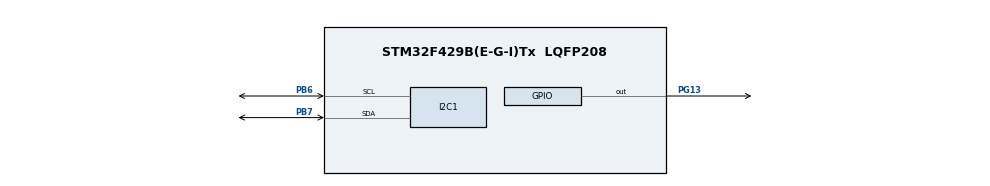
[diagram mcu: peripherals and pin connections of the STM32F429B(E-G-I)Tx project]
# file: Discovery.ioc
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FREERTOS.Tasks01=Led_on_task,2,128,Led_on_task_callback;Led_off_task,2,128,Led_off_task_callback;supervisor,0,128,supervisor_callback
FREERTOS.configTOTAL_HEAP_SIZE=10240
I2C1.OwnAddress=1
Mcu.Family=STM32F4
Mcu.Name=STM32F429B(E-G-I)Tx
Mcu.Package=LQFP208
NVIC.PriorityGroup=NVIC_PRIORITYGROUP_4
PB6.Mode=I2C
PB6.Signal=I2C1_SCL
PB7.Mode=I2C
PB7.Signal=I2C1_SDA
PG13.Signal=GPIO_Output
ProjectManager.TargetToolchain=EWARM
RCC.AHBFreq_Value=16000000
RCC.APB1Freq_Value=16000000
RCC.APB2Freq_Value=16000000
RCC.CortexFreq_Value=16000000
RCC.HSE_VALUE=25000000
RCC.HSI_VALUE=16000000
RCC.LSE_VALUE=32768
RCC.SYSCLKFreq_VALUE=16000000
RCC.VCOOutputFreq_Value=192000000
VP_FREERTOS_VS_ENABLE.Mode=Enabled
board=Discovery

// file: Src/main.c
/**
  ******************************************************************************
  * File Name          : main.c
  * Description        : Main program body
  ******************************************************************************
  *
  * COPYRIGHT(c) 2015 STMicroelectronics
  *
  * Redistribution and use in source and binary forms, with or without modification,
  * are permitted provided that the following conditions are met:
  *   1. Redistributions of source code must retain the above copyright notice,
  *      this list of conditions and the following disclaimer.
  *   2. Redistributions in binary form must reproduce the above copyright notice,
  *      this list of conditions and the following disclaimer in the documentation
  *      and/or other materials provided with the distribution.
  *   3. Neither the name of STMicroelectronics nor the names of its contributors
  *      may be used to endorse or promote products derived from this software
  *      without specific prior written permission.
  *
  * THIS SOFTWARE IS PROVIDED BY THE COPYRIGHT HOLDERS AND CONTRIBUTORS "AS IS"
  * AND ANY EXPRESS OR IMPLIED WARRANTIES, INCLUDING, BUT NOT LIMITED TO, THE
  * IMPLIED WARRANTIES OF MERCHANTABILITY AND FITNESS FOR A PARTICULAR PURPOSE ARE
  * DISCLAIMED. IN NO EVENT SHALL THE COPYRIGHT HOLDER OR CONTRIBUTORS BE LIABLE
  * FOR ANY DIRECT, INDIRECT, INCIDENTAL, SPECIAL, EXEMPLARY, OR CONSEQUENTIAL
  * DAMAGES (INCLUDING, BUT NOT LIMITED TO, PROCUREMENT OF SUBSTITUTE GOODS OR
  * SERVICES; LOSS OF USE, DATA, OR PROFITS; OR BUSINESS INTERRUPTION) HOWEVER
  * CAUSED AND ON ANY THEORY OF LIABILITY, WHETHER IN CONTRACT, STRICT LIABILITY,
  * OR TORT (INCLUDING NEGLIGENCE OR OTHERWISE) ARISING IN ANY WAY OUT OF THE USE
  * OF THIS SOFTWARE, EVEN IF ADVISED OF THE POSSIBILITY OF SUCH DAMAGE.
  *
  ******************************************************************************
  */
#include "stm32f4xx_hal.h"
#include "cmsis_os.h"

I2C_HandleTypeDef hi2c1;

osThreadId Led_on_taskHandle;
osThreadId Led_off_taskHandle;
osThreadId supervisorHandle;

/* USER CODE BEGIN PV */
/* Private variables ---------------------------------------------------------*/
uint8_t pData[1] = {0xF};
/* USER CODE END PV */

void SystemClock_Config(void);
static void MX_GPIO_Init(void);
static void MX_I2C1_Init(void);
void Led_on_task_callback(void const * argument);
void Led_off_task_callback(void const * argument);
void supervisor_callback(void const * argument);

/* USER CODE BEGIN PFP */
/* Private function prototypes -----------------------------------------------*/

/* USER CODE END PFP */

int main(void)
{

  /* MCU Configuration----------------------------------------------------------*/

  /* Reset of all peripherals, Initializes the Flash interface and the Systick. */
  HAL_Init();

  /* Configure the system clock */
  SystemClock_Config();

  /* Initialize all configured peripherals */
  MX_GPIO_Init();
  MX_I2C1_Init();

  /* Create the thread(s) */
  /* definition and creation of Led_on_task */
  osThreadDef(Led_on_task, Led_on_task_callback, osPriorityHigh, 0, 128);
  Led_on_taskHandle = osThreadCreate(osThread(Led_on_task), NULL);

  /* definition and creation of Led_off_task */
  osThreadDef(Led_off_task, Led_off_task_callback, osPriorityHigh, 0, 128);
  Led_off_taskHandle = osThreadCreate(osThread(Led_off_task), NULL);

  /* definition and creation of supervisor */
  osThreadDef(supervisor, supervisor_callback, osPriorityNormal, 0, 128);
  supervisorHandle = osThreadCreate(osThread(supervisor), NULL);

  /* Start scheduler */
  osKernelStart();

  /* We should never get here as control is now taken by the scheduler */

  /* Infinite loop */
  while (1)
  {

  }

}

/** System Clock Configuration
*/
void SystemClock_Config(void)
{

  RCC_OscInitTypeDef RCC_OscInitStruct;

  __PWR_CLK_ENABLE();

  __HAL_PWR_VOLTAGESCALING_CONFIG(PWR_REGULATOR_VOLTAGE_SCALE3);

  RCC_OscInitStruct.OscillatorType = RCC_OSCILLATORTYPE_HSI;
  RCC_OscInitStruct.HSIState = RCC_HSI_ON;
  RCC_OscInitStruct.HSICalibrationValue = 16;
  RCC_OscInitStruct.PLL.PLLState = RCC_PLL_NONE;
  HAL_RCC_OscConfig(&RCC_OscInitStruct);

  HAL_SYSTICK_Config(HAL_RCC_GetHCLKFreq()/1000);

  HAL_SYSTICK_CLKSourceConfig(SYSTICK_CLKSOURCE_HCLK);

  /* SysTick_IRQn interrupt configuration */
  HAL_NVIC_SetPriority(SysTick_IRQn, 15, 0);
}

/* I2C1 init function */
void MX_I2C1_Init(void)
{

  hi2c1.Instance = I2C1;
  hi2c1.Init.ClockSpeed = 100000;
  hi2c1.Init.DutyCycle = I2C_DUTYCYCLE_2;
  hi2c1.Init.OwnAddress1 = 2;
  hi2c1.Init.AddressingMode = I2C_ADDRESSINGMODE_7BIT;
  hi2c1.Init.DualAddressMode = I2C_DUALADDRESS_DISABLED;
  hi2c1.Init.OwnAddress2 = 0;
  hi2c1.Init.GeneralCallMode = I2C_GENERALCALL_DISABLED;
  hi2c1.Init.NoStretchMode = I2C_NOSTRETCH_DISABLED;
  HAL_I2C_Init(&hi2c1);

}

/** Configure pins as
        * Analog
        * Input
        * Output
        * EVENT_OUT
        * EXTI
*/
void MX_GPIO_Init(void)
{

  GPIO_InitTypeDef GPIO_InitStruct;

  /* GPIO Ports Clock Enable */
  __GPIOG_CLK_ENABLE();
  __GPIOB_CLK_ENABLE();

  /*Configure GPIO pin : PG13 */
  GPIO_InitStruct.Pin = GPIO_PIN_13;
  GPIO_InitStruct.Mode = GPIO_MODE_OUTPUT_PP;
  GPIO_InitStruct.Pull = GPIO_NOPULL;
  GPIO_InitStruct.Speed = GPIO_SPEED_LOW;
  HAL_GPIO_Init(GPIOG, &GPIO_InitStruct);

}

/* Led_on_task_callback function */
void Led_on_task_callback(void const * argument)
{

  /* USER CODE BEGIN 5 */
  /* Infinite loop */
  for(;;)
  {
    HAL_GPIO_WritePin(GPIOG, GPIO_PIN_13, GPIO_PIN_SET);
    osThreadSuspend (Led_on_taskHandle);
  }
  /* USER CODE END 5 */
}

/* Led_off_task_callback function */
void Led_off_task_callback(void const * argument)
{
  /* USER CODE BEGIN Led_off_task_callback */
  /* Infinite loop */
  for(;;)
  {
    HAL_GPIO_WritePin(GPIOG, GPIO_PIN_13, GPIO_PIN_RESET);
    osThreadSuspend (Led_off_taskHandle);
  }
  /* USER CODE END Led_off_task_callback */
}

/* supervisor_callback function */
void supervisor_callback(void const * argument)
{
  /* USER CODE BEGIN supervisor_callback */
  /* Infinite loop */

  for(;;)
  {
    if ( HAL_I2C_Slave_Receive(&hi2c1, (uint8_t *)pData, I2C_MEMADD_SIZE_8BIT,100) == HAL_OK)
    {
      if(pData[0] == 0)
      {
        pData[0]=0xFF;
        osThreadResume(Led_off_taskHandle);
       }
      else if(pData[0] == 1)
      {
        pData[0]=0xFF;
        osThreadResume(Led_on_taskHandle);
      }
    }
  }
  /* USER CODE END supervisor_callback */
}

/************************ (C) COPYRIGHT STMicroelectronics *****END OF FILE****/
